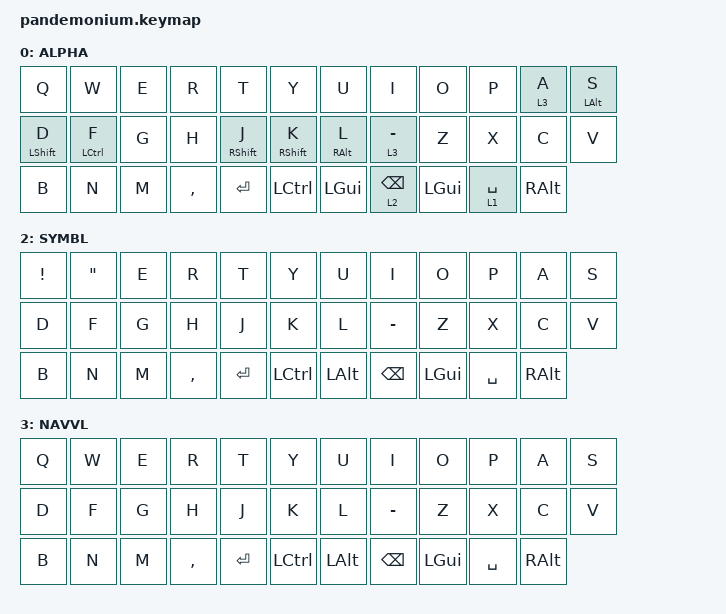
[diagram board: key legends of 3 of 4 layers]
/*
 * Copyright (c) 2020 The ZMK Contributors
 *
 * SPDX-License-Identifier: MIT
 */

#include <behaviors.dtsi>
#include <dt-bindings/zmk/keys.h>

#define ALPHA 0
#define NUMFN 1
#define SYMBL 2
#define NAVVL 3

/ {
    behaviors {
        hm: homerow_mods {
            compatible = "zmk,behavior-hold-tap";
            label = "homerow mods";
            #binding-cells = <2>;
            tapping-term-ms = <225>;
            flavor = "tap-preferred";
            bindings = <&kp>, <&kp>;
        };
    };
};

/ {
    macros {
        sect: sect {
            compatible = "zmk,behavior-macro";
            #binding-cells = <0>;
            bindings = <&kp N0 &kp N0 &kp N0 &kp A &kp N7 &kp LA(X)>;
            label = "SECT";
        };
    };

    keymap {
        compatible = "zmk,keymap";

        ALPHA {
            bindings = <
&kp Q         &kp W        &kp E  &kp R      &kp T         &kp Y           &kp U       &kp I        &kp O     &kp P        &lt 3 A   &mt LALT S
&mt LSHIFT D  &mt LCTRL F  &kp G  &kp H      &mt RSHIFT J  &mt RSHIFT K    &mt RALT L  &lt 3 MINUS  &kp Z     &kp X        &kp C     &kp V
&kp B         &kp N        &kp M  &kp COMMA  &kp RET       &kp LCTRL       &kp LGUI    &lt 2 BSPC   &kp LGUI  &lt 1 SPACE  &kp RALT
            >;
        };

        NUMFN {
            bindings = <
&kp 1    &kp 2            &kp 3         &kp 4         &kp 5      &kp 6                   &kp 7       &kp 8     &kp 9      &kp 0     &kp F1   &kp F2
&kp F3   &kp F4           &kp F5        &kp F6        &trans     &kp KP_PLUS kp UNDER    &kp KP_DOT  &kp F7    &kp F8     &kp F9    &kp F10  &kp F11
&kp F12  &kp KP_ASTERISK  &kp KP_SLASH  &kp KP_EQUAL  &kp LCTRL  &kp LALT                &kp BSPC    &kp LGUI  &kp SPACE  &kp RALT
            >;
        };

        SYMBL {
            bindings = <
&kp EXCL  &kp DQT  &kp E  &kp R      &kp T    &kp Y        &kp U     &kp I      &kp O     &kp P      &kp A     &kp S
&kp D     &kp F    &kp G  &kp H      &kp J    &kp K        &kp L     &kp MINUS  &kp Z     &kp X      &kp C     &kp V
&kp B     &kp N    &kp M  &kp COMMA  &kp RET  &kp LCTRL    &kp LALT  &kp BSPC   &kp LGUI  &kp SPACE  &kp RALT
            >;
        };

        NAVVL {
            bindings = <
&kp Q  &kp W  &kp E  &kp R      &kp T    &kp Y        &kp U     &kp I      &kp O     &kp P      &kp A     &kp S
&kp D  &kp F  &kp G  &kp H      &kp J    &kp K        &kp L     &kp MINUS  &kp Z     &kp X      &kp C     &kp V
&kp B  &kp N  &kp M  &kp COMMA  &kp RET  &kp LCTRL    &kp LALT  &kp BSPC   &kp LGUI  &kp SPACE  &kp RALT
            >;
        };
    };
};
